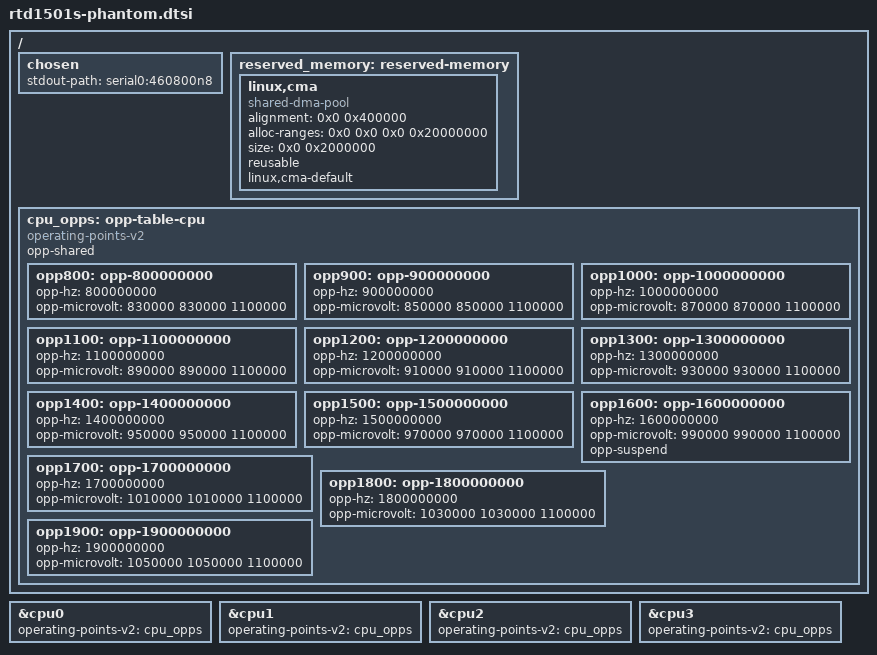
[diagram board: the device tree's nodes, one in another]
// SPDX-License-Identifier: GPL-2.0
/*
 * Realtek RTD1501S Phantom EVB
 *
 * Copyright (c) 2024 Realtek Semiconductor Corp.
 */

/dts-v1/;

#include <dt-bindings/thermal/thermal.h>
#include "rtd1501.dtsi"

/ {
	chosen {
		stdout-path = "serial0:460800n8";
	};

	reserved_memory: reserved-memory {
		#address-cells = <2>;
		#size-cells = <2>;
		ranges;

		linux,cma {
			compatible = "shared-dma-pool";
			alignment = <0x0 0x400000>;
			alloc-ranges = <0x0 0x0 0x0 0x20000000>;
			size = <0x0 0x2000000>;
			reusable;
			linux,cma-default;
		};
	};

	cpu_opps: opp-table-cpu {
		compatible = "operating-points-v2";
		opp-shared;

		opp800: opp-800000000 {
			opp-hz = /bits/ 64 <800000000>;
			opp-microvolt = <830000 830000 1100000>;
		};

		opp900: opp-900000000 {
			opp-hz = /bits/ 64 <900000000>;
			opp-microvolt = <850000 850000 1100000>;
		};

		opp1000: opp-1000000000 {
			opp-hz = /bits/ 64 <1000000000>;
			opp-microvolt = <870000 870000 1100000>;
		};

		opp1100: opp-1100000000 {
			opp-hz = /bits/ 64 <1100000000>;
			opp-microvolt = <890000 890000 1100000>;
		};

		opp1200: opp-1200000000 {
			opp-hz = /bits/ 64 <1200000000>;
			opp-microvolt = <910000 910000 1100000>;
		};

		opp1300: opp-1300000000 {
			opp-hz = /bits/ 64 <1300000000>;
			opp-microvolt = <930000 930000 1100000>;
		};

		opp1400: opp-1400000000 {
			opp-hz = /bits/ 64 <1400000000>;
			opp-microvolt = <950000 950000 1100000>;
		};

		opp1500: opp-1500000000 {
			opp-hz = /bits/ 64 <1500000000>;
			opp-microvolt = <970000 970000 1100000>;
		};

		opp1600: opp-1600000000 {
			opp-hz = /bits/ 64 <1600000000>;
			opp-microvolt = <990000 990000 1100000>;
			opp-suspend;
		};

		opp1700: opp-1700000000 {
			opp-hz = /bits/ 64 <1700000000>;
			opp-microvolt = <1010000 1010000 1100000>;
		};

		opp1800: opp-1800000000 {
			opp-hz = /bits/ 64 <1800000000>;
			opp-microvolt = <1030000 1030000 1100000>;
		};

		opp1900: opp-1900000000 {
			opp-hz = /bits/ 64 <1900000000>;
			opp-microvolt = <1050000 1050000 1100000>;
		};
	};
};

&cpu0 {
	operating-points-v2 = <&cpu_opps>;
	#cooling-cells = <2>;
};

&cpu1 {
	operating-points-v2 = <&cpu_opps>;
	#cooling-cells = <2>;
};

&cpu2 {
	operating-points-v2 = <&cpu_opps>;
	#cooling-cells = <2>;
};

&cpu3 {
	operating-points-v2 = <&cpu_opps>;
	#cooling-cells = <2>;
};
